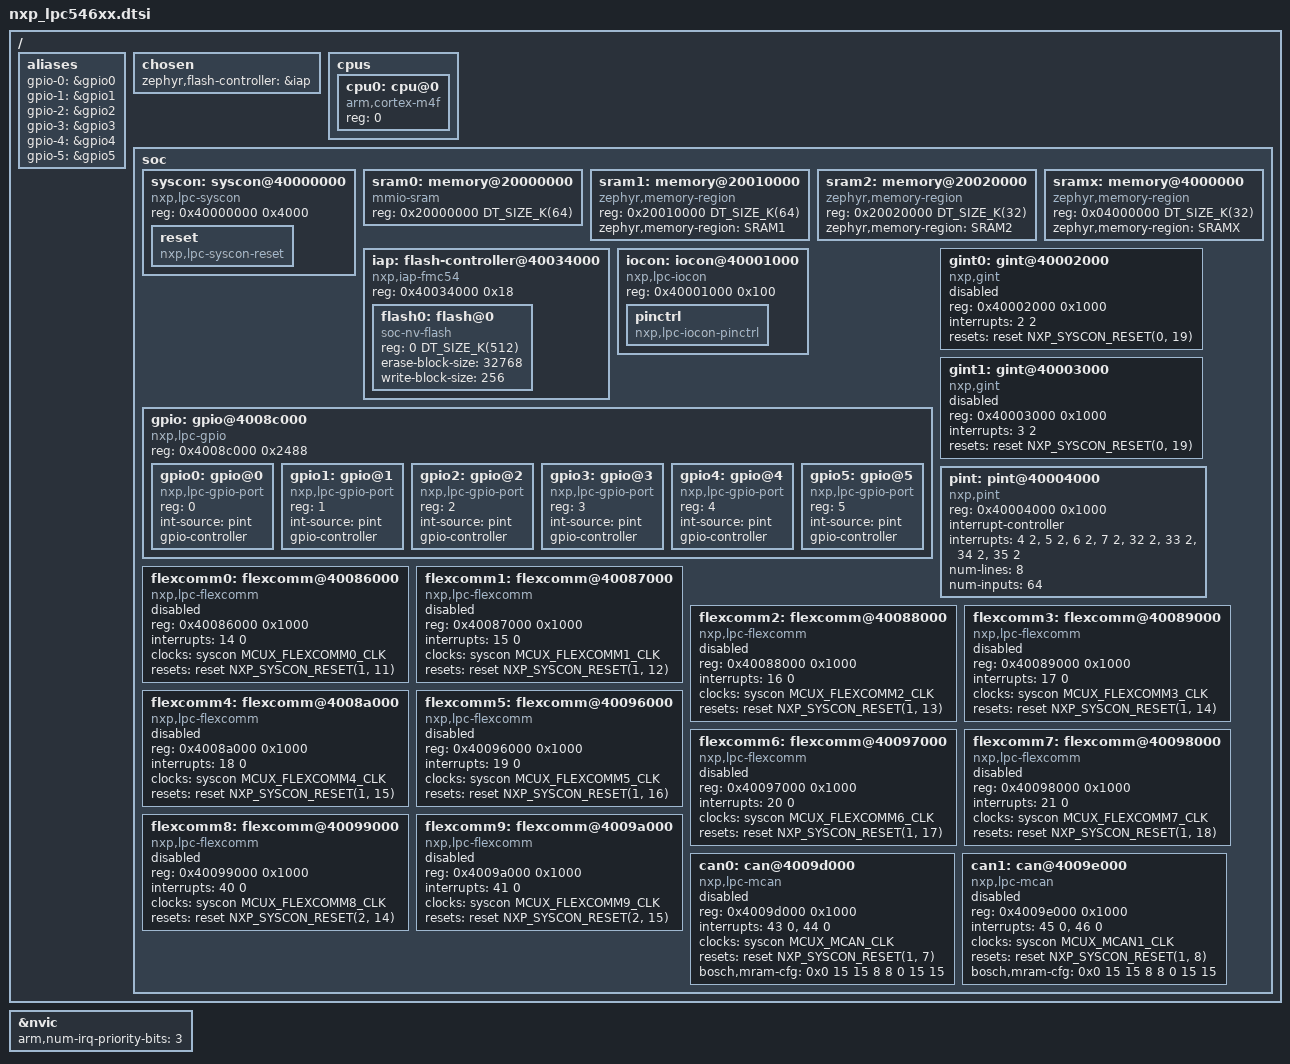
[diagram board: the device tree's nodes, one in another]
/*
 * Copyright 2017, 2026 NXP
 *
 * SPDX-License-Identifier: Apache-2.0
 */

#include <arm/armv7-m.dtsi>
#include <mem.h>
#include <freq.h>
#include <zephyr/dt-bindings/clock/mcux_lpc_syscon_clock.h>
#include <zephyr/dt-bindings/gpio/gpio.h>
#include <zephyr/dt-bindings/i2c/i2c.h>
#include <zephyr/dt-bindings/reset/nxp_syscon_reset_common.h>

/ {
	aliases {
		gpio-0 = &gpio0;
		gpio-1 = &gpio1;
		gpio-2 = &gpio2;
		gpio-3 = &gpio3;
		gpio-4 = &gpio4;
		gpio-5 = &gpio5;
	};

	chosen {
		zephyr,flash-controller = &iap;
	};

	cpus {
		#address-cells = <1>;
		#size-cells = <0>;

		cpu0: cpu@0 {
			compatible = "arm,cortex-m4f";
			reg = <0>;
		};
	};

	soc {
		syscon: syscon@40000000 {
			compatible = "nxp,lpc-syscon";
			reg = <0x40000000 0x4000>;
			#clock-cells = <1>;

			reset: reset {
				compatible = "nxp,lpc-syscon-reset";
				#reset-cells = <1>;
			};
		};

		/*
		 * LPC546xx main SRAM is three contiguous banks at 0x20000000:
		 * SRAM0 (64K) + SRAM1 (64K) + SRAM2 (32K) = 160K. Each bank is a
		 * separate node; sram0 covers the SRAM0 bank only. A board that
		 * wants the full contiguous 160K overrides sram0's reg (see
		 * lpcxpresso54628). SRAMX is a separate 32K code RAM bank at
		 * 0x04000000.
		 */
		sram0: memory@20000000 {
			compatible = "mmio-sram";
			reg = <0x20000000 DT_SIZE_K(64)>;
		};

		sram1: memory@20010000 {
			compatible = "zephyr,memory-region", "mmio-sram";
			reg = <0x20010000 DT_SIZE_K(64)>;
			zephyr,memory-region = "SRAM1";
		};

		sram2: memory@20020000 {
			compatible = "zephyr,memory-region", "mmio-sram";
			reg = <0x20020000 DT_SIZE_K(32)>;
			zephyr,memory-region = "SRAM2";
		};

		sramx: memory@4000000 {
			compatible = "zephyr,memory-region", "mmio-sram";
			reg = <0x04000000 DT_SIZE_K(32)>;
			zephyr,memory-region = "SRAMX";
		};

		iap: flash-controller@40034000 {
			compatible = "nxp,iap-fmc54";
			reg = <0x40034000 0x18>;
			#address-cells = <1>;
			#size-cells = <1>;

			flash0: flash@0 {
				compatible = "soc-nv-flash";
				reg = <0 DT_SIZE_K(512)>;
				erase-block-size = <32768>;
				write-block-size = <256>;
			};
		};

		iocon: iocon@40001000 {
			compatible = "nxp,lpc-iocon";
			reg = <0x40001000 0x100>;
			#address-cells = <1>;
			#size-cells = <1>;
			ranges = <0x0 0x40001000 0x100>;

			pinctrl: pinctrl {
				compatible = "nxp,lpc-iocon-pinctrl";
			};
		};

		gpio: gpio@4008c000 {
			compatible = "nxp,lpc-gpio";
			reg = <0x4008c000 0x2488>;
			#address-cells = <1>;
			#size-cells = <0>;

			gpio0: gpio@0 {
				compatible = "nxp,lpc-gpio-port";
				reg = <0>;
				int-source = "pint";
				gpio-controller;
				#gpio-cells = <2>;
			};

			gpio1: gpio@1 {
				compatible = "nxp,lpc-gpio-port";
				reg = <1>;
				int-source = "pint";
				gpio-controller;
				#gpio-cells = <2>;
			};

			gpio2: gpio@2 {
				compatible = "nxp,lpc-gpio-port";
				reg = <2>;
				int-source = "pint";
				gpio-controller;
				#gpio-cells = <2>;
			};

			gpio3: gpio@3 {
				compatible = "nxp,lpc-gpio-port";
				reg = <3>;
				int-source = "pint";
				gpio-controller;
				#gpio-cells = <2>;
			};

			gpio4: gpio@4 {
				compatible = "nxp,lpc-gpio-port";
				reg = <4>;
				int-source = "pint";
				gpio-controller;
				#gpio-cells = <2>;
			};

			gpio5: gpio@5 {
				compatible = "nxp,lpc-gpio-port";
				reg = <5>;
				int-source = "pint";
				gpio-controller;
				#gpio-cells = <2>;
			};
		};

		gint0: gint@40002000 {
			compatible = "nxp,gint";
			reg = <0x40002000 0x1000>;
			interrupts = <2 2>;
			resets = <&reset NXP_SYSCON_RESET(0, 19)>;
			status = "disabled";
		};

		gint1: gint@40003000 {
			compatible = "nxp,gint";
			reg = <0x40003000 0x1000>;
			interrupts = <3 2>;
			resets = <&reset NXP_SYSCON_RESET(0, 19)>;
			status = "disabled";
		};

		pint: pint@40004000 {
			compatible = "nxp,pint";
			reg = <0x40004000 0x1000>;
			interrupt-controller;
			#interrupt-cells = <1>;
			#address-cells = <0>;
			interrupts = <4 2>, <5 2>, <6 2>, <7 2>,
				     <32 2>, <33 2>, <34 2>, <35 2>;
			num-lines = <8>;
			num-inputs = <64>;
		};

		flexcomm0: flexcomm@40086000 {
			compatible = "nxp,lpc-flexcomm";
			reg = <0x40086000 0x1000>;
			interrupts = <14 0>;
			clocks = <&syscon MCUX_FLEXCOMM0_CLK>;
			resets = <&reset NXP_SYSCON_RESET(1, 11)>;
			status = "disabled";
		};

		flexcomm1: flexcomm@40087000 {
			compatible = "nxp,lpc-flexcomm";
			reg = <0x40087000 0x1000>;
			interrupts = <15 0>;
			clocks = <&syscon MCUX_FLEXCOMM1_CLK>;
			resets = <&reset NXP_SYSCON_RESET(1, 12)>;
			status = "disabled";
		};

		flexcomm2: flexcomm@40088000 {
			compatible = "nxp,lpc-flexcomm";
			reg = <0x40088000 0x1000>;
			interrupts = <16 0>;
			clocks = <&syscon MCUX_FLEXCOMM2_CLK>;
			resets = <&reset NXP_SYSCON_RESET(1, 13)>;
			status = "disabled";
		};

		flexcomm3: flexcomm@40089000 {
			compatible = "nxp,lpc-flexcomm";
			reg = <0x40089000 0x1000>;
			interrupts = <17 0>;
			clocks = <&syscon MCUX_FLEXCOMM3_CLK>;
			resets = <&reset NXP_SYSCON_RESET(1, 14)>;
			status = "disabled";
		};

		flexcomm4: flexcomm@4008a000 {
			compatible = "nxp,lpc-flexcomm";
			reg = <0x4008a000 0x1000>;
			interrupts = <18 0>;
			clocks = <&syscon MCUX_FLEXCOMM4_CLK>;
			resets = <&reset NXP_SYSCON_RESET(1, 15)>;
			status = "disabled";
		};

		flexcomm5: flexcomm@40096000 {
			compatible = "nxp,lpc-flexcomm";
			reg = <0x40096000 0x1000>;
			interrupts = <19 0>;
			clocks = <&syscon MCUX_FLEXCOMM5_CLK>;
			resets = <&reset NXP_SYSCON_RESET(1, 16)>;
			status = "disabled";
		};

		flexcomm6: flexcomm@40097000 {
			compatible = "nxp,lpc-flexcomm";
			reg = <0x40097000 0x1000>;
			interrupts = <20 0>;
			clocks = <&syscon MCUX_FLEXCOMM6_CLK>;
			resets = <&reset NXP_SYSCON_RESET(1, 17)>;
			status = "disabled";
		};

		flexcomm7: flexcomm@40098000 {
			compatible = "nxp,lpc-flexcomm";
			reg = <0x40098000 0x1000>;
			interrupts = <21 0>;
			clocks = <&syscon MCUX_FLEXCOMM7_CLK>;
			resets = <&reset NXP_SYSCON_RESET(1, 18)>;
			status = "disabled";
		};

		flexcomm8: flexcomm@40099000 {
			compatible = "nxp,lpc-flexcomm";
			reg = <0x40099000 0x1000>;
			interrupts = <40 0>;
			clocks = <&syscon MCUX_FLEXCOMM8_CLK>;
			resets = <&reset NXP_SYSCON_RESET(2, 14)>;
			status = "disabled";
		};

		flexcomm9: flexcomm@4009a000 {
			compatible = "nxp,lpc-flexcomm";
			reg = <0x4009a000 0x1000>;
			interrupts = <41 0>;
			clocks = <&syscon MCUX_FLEXCOMM9_CLK>;
			resets = <&reset NXP_SYSCON_RESET(2, 15)>;
			status = "disabled";
		};

		can0: can@4009d000 {
			compatible = "nxp,lpc-mcan";
			reg = <0x4009d000 0x1000>;
			interrupts = <43 0>, <44 0>;
			interrupt-names = "int0", "int1";
			clocks = <&syscon MCUX_MCAN_CLK>;
			resets = <&reset NXP_SYSCON_RESET(1, 7)>;
			bosch,mram-cfg = <0x0 15 15 8 8 0 15 15>;
			status = "disabled";
		};

		can1: can@4009e000 {
			compatible = "nxp,lpc-mcan";
			reg = <0x4009e000 0x1000>;
			interrupts = <45 0>, <46 0>;
			interrupt-names = "int0", "int1";
			clocks = <&syscon MCUX_MCAN1_CLK>;
			resets = <&reset NXP_SYSCON_RESET(1, 8)>;
			bosch,mram-cfg = <0x0 15 15 8 8 0 15 15>;
			status = "disabled";
		};
	};
};

&nvic {
	arm,num-irq-priority-bits = <3>;
};
